# M3V6 register map
File version: 0.1
Registers are 32-bit, read-write, reset 0x0 unless marked. A register's access mark holds for its fields unless they carry their own. Offsets are from the block's base; [hi:lo] are bit positions; {n}, {i} and the like mark numbered series.

## AD — Analog-to-Digital Converter (AD)
Base 0x40030000
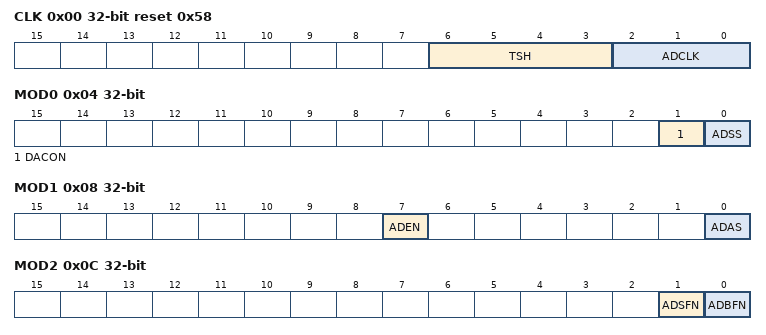
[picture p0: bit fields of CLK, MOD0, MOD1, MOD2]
0x00 CLK reset 0x58 — AD Conversion Clock Setting Register
  [6:3] TSH, [2:0] ADCLK
0x04 MOD0 — AD Mode Control Register 0
  [1] DACON, [0] ADSS wo
0x08 MOD1 — AD Mode Control Register 1
  [7] ADEN, [0] ADAS
0x0C MOD2 ro — AD Mode Control Register 2
  [1] ADSFN, [0] ADBFN
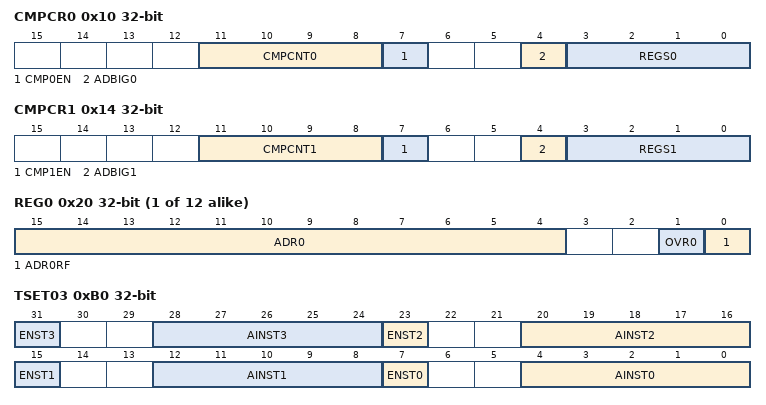
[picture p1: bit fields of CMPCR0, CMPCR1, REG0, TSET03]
0x10 CMPCR0 — AD Monitoring Setting Register 0
  [11:8] CMPCNT0, [7] CMP0EN, [4] ADBIG0, [3:0] REGS0
0x14 CMPCR1 — AD Monitoring Setting Register 1
  [11:8] CMPCNT1, [7] CMP1EN, [4] ADBIG1, [3:0] REGS1
0x18 CMP0 — AD Conversion Result Comparison Register 0
  [15:4] AD0CMP
0x1C CMP1 — AD Conversion Result Comparison Register 1
  [15:4] AD1CMP
{0x20+4i} REG{i} ro (i=0..11) — AD Conversion Result Register {i:02}
  [15:4] ADR{i}, [1] OVR{i}, [0] ADR{i}RF
0xB0 TSET03 — Timer Trigger Program Register 03
  [8n+7] ENST{n} (n=0..3), [8n+4:8n] AINST{n} (n=0..3)
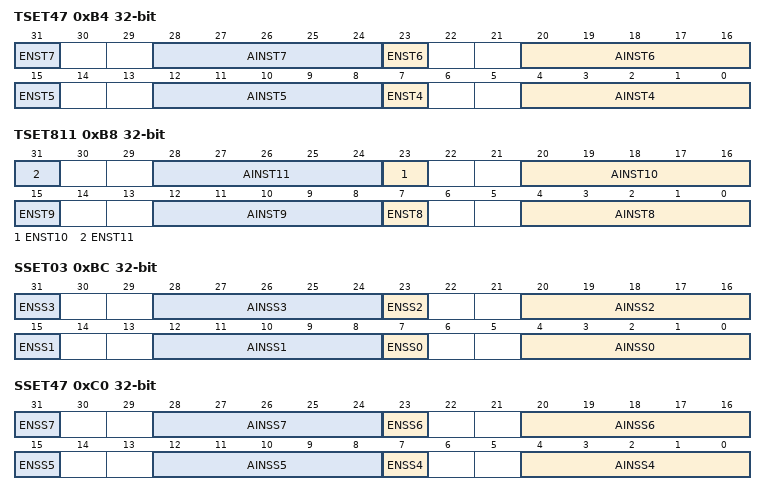
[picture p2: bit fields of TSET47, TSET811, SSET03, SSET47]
0xB4 TSET47 — Timer Trigger Program Register 47
  [8n-25] ENST{n} (n=4..7), [8n-28:8n-32] AINST{n} (n=4..7)
0xB8 TSET811 — Timer Trigger Program Register 811
  [8n-57] ENST{n} (n=8..11), [8n-60:8n-64] AINST{n} (n=8..11)
0xBC SSET03 — Software Trigger Program Register 03
  [8n+7] ENSS{n} (n=0..3), [8n+4:8n] AINSS{n} (n=0..3)
0xC0 SSET47 — Software Trigger Program Register 47
  [8n-25] ENSS{n} (n=4..7), [8n-28:8n-32] AINSS{n} (n=4..7)
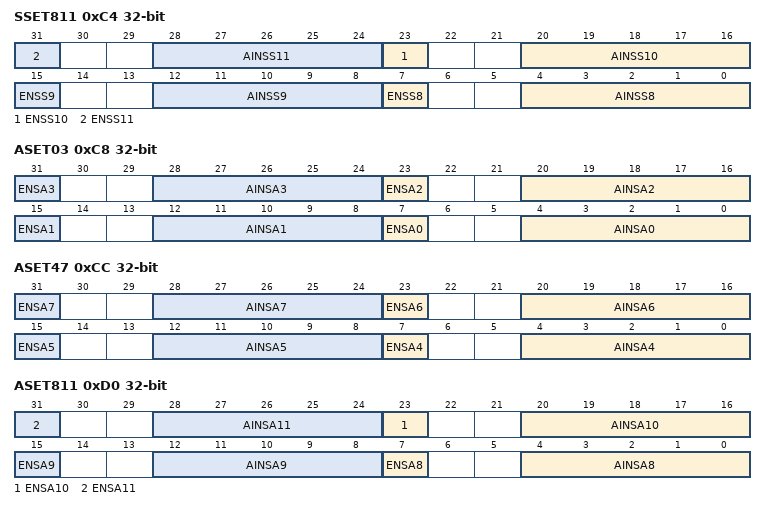
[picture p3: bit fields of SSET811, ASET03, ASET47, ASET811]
0xC4 SSET811 — Software Trigger Program Register 811
  [8n-57] ENSS{n} (n=8..11), [8n-60:8n-64] AINSS{n} (n=8..11)
0xC8 ASET03 — Constant Conversion Program Register 03
  [8n+7] ENSA{n} (n=0..3), [8n+4:8n] AINSA{n} (n=0..3)
0xCC ASET47 — Constant Conversion Program Register 47
  [8n-25] ENSA{n} (n=4..7), [8n-28:8n-32] AINSA{n} (n=4..7)
0xD0 ASET811 — Constant Conversion Program Register 811
  [8n-57] ENSA{n} (n=8..11), [8n-60:8n-64] AINSA{n} (n=8..11)
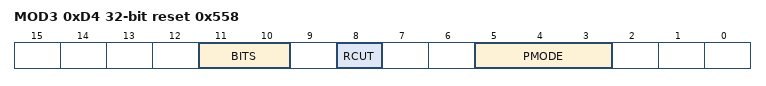
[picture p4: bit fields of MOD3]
0xD4 MOD3 reset 0x558 — AD Mode Control Register 3
  [11:10] BITS, [8] RCUT, [5:3] PMODE

## WD — Watchdog Timer (WD)
Base 0x40040000
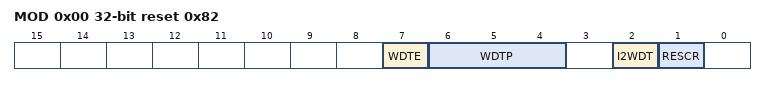
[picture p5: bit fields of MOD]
0x00 MOD reset 0x82 — WD Mode Register
  [7] WDTE, [6:4] WDTP, [2] I2WDT, [1] RESCR
0x04 CR wo (reset mask 0xFFFFFF00) — WD Control Register
  [7:0] WDCR

## RTC — Real Time Clock (RTC)
Base 0x40040100
0x00 SECR 8-bit (reset mask 0x80) — RTC Second Column Register
  [6:0] SE
0x01 MINR 8-bit (reset mask 0x80) — RTC Minute Column Register
  [6:0] MI
0x02 HOURR 8-bit (reset mask 0xC0) — RTC Hour Column Register
  [5:0] HO
0x04 DAYR 8-bit (reset mask 0xF8) — RTC Day of the Week Column Register
  [2:0] WE
0x05 DATER 8-bit (reset mask 0xC0) — RTC Day Column Register
  [5:0] DA
0x06 MONTHR_A 8-bit (reset mask 0xE0) — RTC Month Column Register
  [4:0] MO
0x06 MONTHR_B 8-bit (reset mask 0xFE) (RTC_MONTHR view) — RTC Month Column Register
  [0] MO0
0x07 YEARR_A 8-bit reset not defined — RTC Year Column Register
  [7:0] YE
0x07 YEARR_B 8-bit (reset mask 0xFC) (RTC_YEARR view) — RTC Year Column Register
  [1:0] LEAP
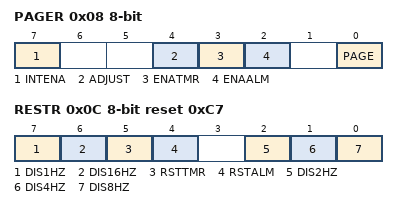
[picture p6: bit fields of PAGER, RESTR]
0x08 PAGER 8-bit (reset mask 0xF3) — RTC PAGE Register
  [7] INTENA, [4] ADJUST, [3] ENATMR, [2] ENAALM, [0] PAGE
0x0C RESTR 8-bit reset 0xC7 — RTC Reset Register
  [7] DIS1HZ, [6] DIS16HZ, [5] RSTTMR, [4] RSTALM, [2] DIS2HZ, [1] DIS4HZ, [0] DIS8HZ

## CG — Clock Generator (CG)
Base 0x40040200
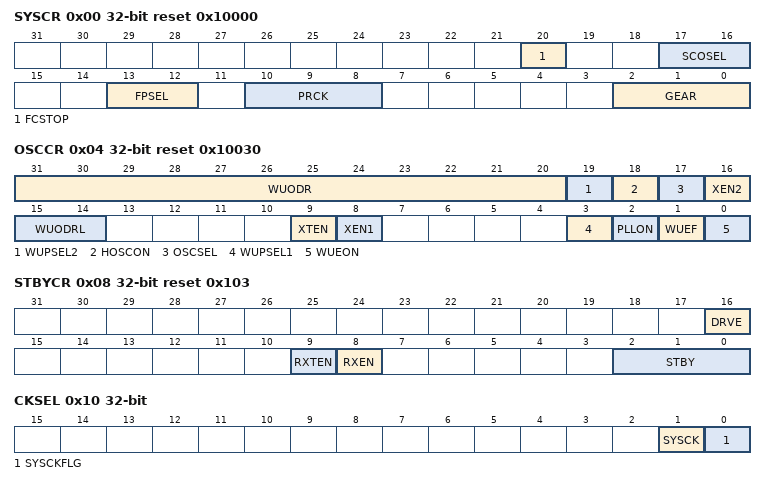
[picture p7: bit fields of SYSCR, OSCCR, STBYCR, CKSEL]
0x00 SYSCR reset 0x10000 — System Control Register
  [20] FCSTOP, [17:16] SCOSEL, [13:12] FPSEL, [10:8] PRCK, [2:0] GEAR
0x04 OSCCR reset 0x10030 — Oscillation Control Register
  [31:20] WUODR, [19] WUPSEL2, [18] HOSCON, [17] OSCSEL, [16] XEN2, [15:14] WUODRL, [9] XTEN, [8] XEN1, [3] WUPSEL1, [2] PLLON, [1] WUEF ro, [0] WUEON wo
0x08 STBYCR reset 0x103 — Standby Control Register
  [16] DRVE, [9] RXTEN, [8] RXEN, [2:0] STBY
0x0C PLLSEL reset 0x721E — PLL Selection Register
  [0] PLLSEL
0x10 CKSEL — System Clock Selection Register
  [1] SYSCK, [0] SYSCKFLG ro
0x14 ICRCG wo — CG Interrupt Request Clear Register
  [4:0] ICRCG
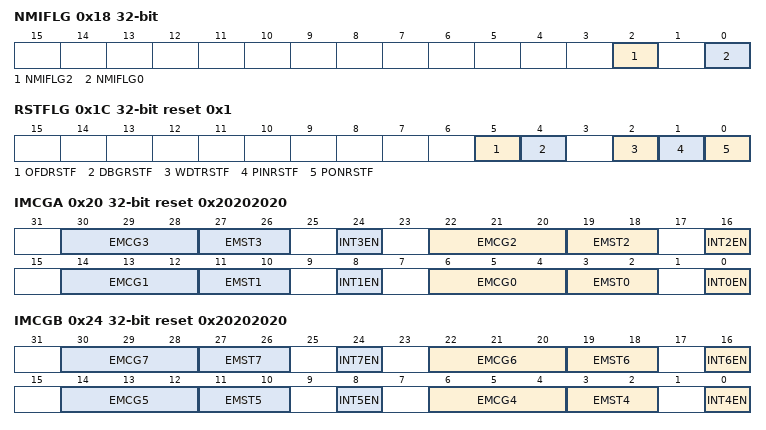
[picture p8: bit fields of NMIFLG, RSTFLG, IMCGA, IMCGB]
0x18 NMIFLG ro — NMI Flag Register
  [2] NMIFLG2, [0] NMIFLG0
0x1C RSTFLG reset 0x1 — Reset Flag Register
  [5] OFDRSTF, [4] DBGRSTF, [2] WDTRSTF, [1] PINRSTF, [0] PONRSTF
0x20 IMCGA reset 0x20202020 — CG Interrupt Mode Control Register A
  [8n+6:8n+4] EMCG{n} (n=0..3), [8n+3:8n+2] EMST{n} ro (n=0..3), [8n] INT{n}EN (n=0..3)
0x24 IMCGB reset 0x20202020 — CG Interrupt Mode Control Register B
  [8n-26:8n-28] EMCG{n} (n=4..7), [8n-29:8n-30] EMST{n} ro (n=4..7), [8n-32] INT{n}EN (n=4..7)
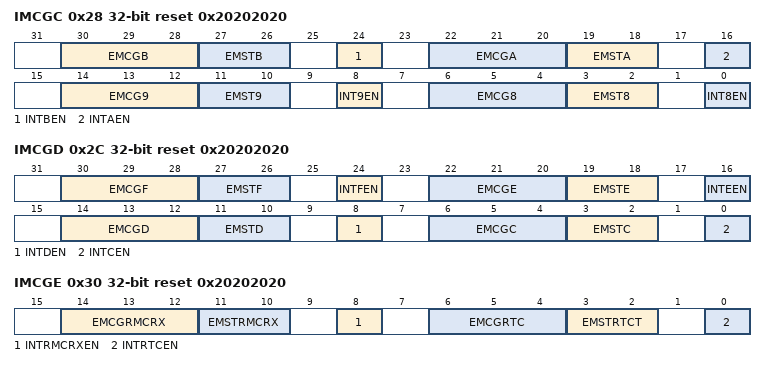
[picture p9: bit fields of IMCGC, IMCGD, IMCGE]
0x28 IMCGC reset 0x20202020 — CG Interrupt Mode Control Register C
  [30:28] EMCGB, [27:26] EMSTB ro, [24] INTBEN, [22:20] EMCGA, [19:18] EMSTA ro, [16] INTAEN, [14:12] EMCG9, [11:10] EMST9 ro, [8] INT9EN, [6:4] EMCG8, [3:2] EMST8 ro, [0] INT8EN
0x2C IMCGD reset 0x20202020 — CG Interrupt Mode Control Register D
  [30:28] EMCGF, [27:26] EMSTF ro, [24] INTFEN, [22:20] EMCGE, [19:18] EMSTE ro, [16] INTEEN, [14:12] EMCGD, [11:10] EMSTD ro, [8] INTDEN, [6:4] EMCGC, [3:2] EMSTC ro, [0] INTCEN
0x30 IMCGE reset 0x20202020 — CG Interrupt Mode Control Register E
  [14:12] EMCGRMCRX, [11:10] EMSTRMCRX ro, [8] INTRMCRXEN, [6:4] EMCGRTC, [3:2] EMSTRTCT ro, [0] INTRTCEN
